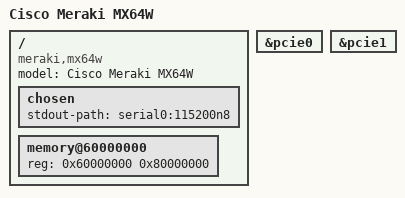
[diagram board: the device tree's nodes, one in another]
/dts-v1/;
#include "bcm958625-meraki-kingpin.dtsi"
/ {
	model = "Cisco Meraki MX64W";
	compatible = "meraki,mx64w", "brcm,bcm58625", "brcm,nsp";
	chosen {
		stdout-path = "serial0:115200n8";
	};
	memory@60000000 {
		device_type = "memory";
		reg = <0x60000000 0x80000000>;
	};
};
&pcie0 {
	status = "okay";
};
&pcie1 {
	status = "okay";
};
